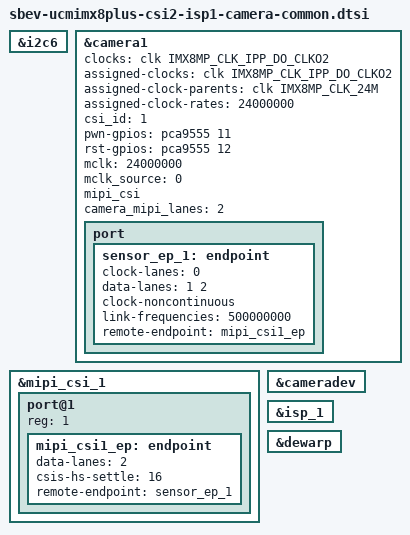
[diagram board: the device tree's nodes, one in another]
// SPDX-License-Identifier: GPL-2.0-only OR MIT

&i2c6 {
	status = "okay";
};

&camera1 {
	clocks = <&clk IMX8MP_CLK_IPP_DO_CLKO2>;
	clock-names = "xclk";
	assigned-clocks = <&clk IMX8MP_CLK_IPP_DO_CLKO2>;
	assigned-clock-parents = <&clk IMX8MP_CLK_24M>;
	assigned-clock-rates = <24000000>;
	csi_id = <1>;
	pwn-gpios = <&pca9555 11 GPIO_ACTIVE_HIGH>;
	rst-gpios = <&pca9555 12 GPIO_ACTIVE_HIGH>;
	mclk = <24000000>;
	mclk_source = <0>;
	mipi_csi;
	camera_mipi_lanes = <2>;
	status = "okay";

	port {
		sensor_ep_1: endpoint {
			clock-lanes = <0>;
			data-lanes = <1 2>;
			clock-noncontinuous;
			link-frequencies = /bits/ 64 <500000000>;
			remote-endpoint = <&mipi_csi1_ep>;
		};
	};
};

&mipi_csi_1 {
	#address-cells = <1>;
	#size-cells = <0>;
	status = "okay";

	port@1 {
		reg = <1>;
		mipi_csi1_ep: endpoint {
			data-lanes = <2>;
			csis-hs-settle = <16>;
			remote-endpoint = <&sensor_ep_1>;
		};
	};
};

&cameradev {
	status = "okay";
};

&isp_1 {
	status = "okay";
};

&dewarp {
	status = "okay";
};
